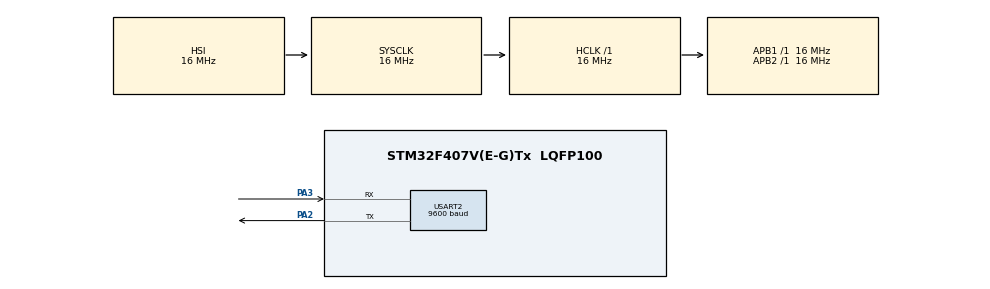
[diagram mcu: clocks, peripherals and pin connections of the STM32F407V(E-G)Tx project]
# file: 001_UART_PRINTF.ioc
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FREERTOS.Tasks01=task2,0,128,gorev2,Default,NULL,Dynamic,NULL,NULL;task1,-3,128,gorev1,Default,NULL,Dynamic,NULL,NULL
FREERTOS.configUSE_NEWLIB_REENTRANT=1
Mcu.Family=STM32F4
Mcu.Name=STM32F407V(E-G)Tx
Mcu.Package=LQFP100
NVIC.PriorityGroup=NVIC_PRIORITYGROUP_4
NVIC.TIM1_UP_TIM10_IRQn=true\:15\:0\:false\:false\:true\:false\:false\:true\:true
NVIC.TimeBase=TIM1_UP_TIM10_IRQn
NVIC.TimeBaseIP=TIM1
NVIC.USART2_IRQn=true\:5\:0\:false\:false\:true\:true\:true\:true\:true
PA2.Mode=Asynchronous
PA2.Signal=USART2_TX
PA3.Mode=Asynchronous
PA3.Signal=USART2_RX
ProjectManager.HeapSize=0x200
ProjectManager.StackSize=0x400
ProjectManager.TargetToolchain=STM32CubeIDE
RCC.AHBFreq_Value=16000000
RCC.APB1Freq_Value=16000000
RCC.APB2Freq_Value=16000000
RCC.CortexFreq_Value=16000000
RCC.HSE_VALUE=25000000
RCC.HSI_VALUE=16000000
RCC.LSE_VALUE=32768
RCC.SYSCLKFreq_VALUE=16000000
RCC.VCOOutputFreq_Value=192000000
USART2.BaudRate=9600
USART2.VirtualMode=VM_ASYNC
VP_FREERTOS_VS_CMSIS_V1.Mode=CMSIS_V1
VP_SYS_VS_tim1.Mode=TIM1
board=custom

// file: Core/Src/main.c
/* USER CODE BEGIN Header */
/**
  ******************************************************************************
  * @file           : main.c
  * @brief          : Main program body
  ******************************************************************************
  * @attention
  *
  * Copyright (c) 2025 STMicroelectronics.
  * All rights reserved.
  *
  * This software is licensed under terms that can be found in the LICENSE file
  * in the root directory of this software component.
  * If no LICENSE file comes with this software, it is provided AS-IS.
  *
  ******************************************************************************
  */
/* USER CODE END Header */
#include "main.h"
#include "cmsis_os.h"

/* USER CODE BEGIN Includes */

#include "stdio.h"
#include <string.h>

/* USER CODE END Includes */

/* USER CODE BEGIN PTD */

#define RED  "\x1B[31m"
#define GRN  "\x1B[32m"

#define RST  "\033[0m"
#define CLR_LINE "\r\033[K"

/* USER CODE END PTD */

/* USER CODE BEGIN PD */

#ifndef STDIN_FILENO
#define STDIN_FILENO 0
#endif

#ifndef STDOUT_FILENO
#define STDOUT_FILENO 1
#endif

#ifndef STDERR_FILENO
#define STDERR_FILENO 2
#endif

/* USER CODE END PD */

UART_HandleTypeDef huart2;

osThreadId task2Handle;
osThreadId task1Handle;
/* USER CODE BEGIN PV */

	uint8_t rxData;
	HAL_StatusTypeDef status;
	char ch[6];
	char input[10];

/* USER CODE END PV */

void SystemClock_Config(void);
static void MX_GPIO_Init(void);
static void MX_USART2_UART_Init(void);
void gorev2(void const * argument);
void gorev1(void const * argument);

/* USER CODE BEGIN 0 */

int _write(int file, char *ptr, int len)
{
	if(file==STDERR_FILENO)
	{
		HAL_UART_Transmit(&huart2, (uint8_t*)RED, strlen(RED) , HAL_MAX_DELAY);
		HAL_UART_Transmit(&huart2, (uint8_t*)ptr, len , HAL_MAX_DELAY);
		HAL_UART_Transmit(&huart2, (uint8_t*)RST, strlen(RST) , HAL_MAX_DELAY);
	}

	else if(file==STDOUT_FILENO)
	{
		HAL_UART_Transmit(&huart2, (uint8_t*)GRN, strlen(GRN) , HAL_MAX_DELAY);
		HAL_UART_Transmit(&huart2, (uint8_t*)ptr, len , HAL_MAX_DELAY);
		HAL_UART_Transmit(&huart2, (uint8_t*)RST, strlen(GRN) , HAL_MAX_DELAY);
	}
	else
	{
		HAL_UART_Transmit(&huart2, (uint8_t*)ptr, len , HAL_MAX_DELAY);

	}
	return len;
}

int _read(int file, char *ptr, int len)
{
    if (file == STDIN_FILENO)
    {
        int i = 0;
        uint8_t ch;

        while (i < len - 1)
        {
            // 1 saniye zaman aşımı ile tek karakter oku
            HAL_StatusTypeDef status = HAL_UART_Receive(&huart2, &ch, 1, 1000);
            if (status == HAL_OK)
            {
                if (ch == '\r' || ch == '\n') // CR veya LF gelirse sonlandır
                {
                    ptr[i] = '\0';
                    break;
                }
                ptr[i++] = ch;
            }
            else
            {
                // Hata veya zaman aşımı durumunda
                ptr[i] = '\0';
                fprintf(stderr, "UART read error: %d\r\n", status);
                return i; // Alınan veriyi döndür veya 0
            }
        }
        ptr[i] = '\0';
        return i;
    }
    return 0;
}

/* USER CODE END 0 */

int main(void)
{

  /* MCU Configuration--------------------------------------------------------*/

  /* Reset of all peripherals, Initializes the Flash interface and the Systick. */
  HAL_Init();

  /* Configure the system clock */
  SystemClock_Config();

  /* Initialize all configured peripherals */
  MX_GPIO_Init();
  MX_USART2_UART_Init();

  /* Create the thread(s) */
  /* definition and creation of task2 */
  osThreadDef(task2, gorev2, osPriorityNormal, 0, 128);
  task2Handle = osThreadCreate(osThread(task2), NULL);

  /* definition and creation of task1 */
  osThreadDef(task1, gorev1, osPriorityIdle, 0, 128);
  task1Handle = osThreadCreate(osThread(task1), NULL);

  /* Start scheduler */
  osKernelStart();

  /* We should never get here as control is now taken by the scheduler */

  /* Infinite loop */
  while (1)
  {

  }
}

void SystemClock_Config(void)
{
  RCC_OscInitTypeDef RCC_OscInitStruct = {0};
  RCC_ClkInitTypeDef RCC_ClkInitStruct = {0};

  /** Configure the main internal regulator output voltage
  */
  __HAL_RCC_PWR_CLK_ENABLE();
  __HAL_PWR_VOLTAGESCALING_CONFIG(PWR_REGULATOR_VOLTAGE_SCALE1);

  /** Initializes the RCC Oscillators according to the specified parameters
  * in the RCC_OscInitTypeDef structure.
  */
  RCC_OscInitStruct.OscillatorType = RCC_OSCILLATORTYPE_HSI;
  RCC_OscInitStruct.HSIState = RCC_HSI_ON;
  RCC_OscInitStruct.HSICalibrationValue = RCC_HSICALIBRATION_DEFAULT;
  RCC_OscInitStruct.PLL.PLLState = RCC_PLL_NONE;
  if (HAL_RCC_OscConfig(&RCC_OscInitStruct) != HAL_OK)
  {
    Error_Handler();
  }

  /** Initializes the CPU, AHB and APB buses clocks
  */
  RCC_ClkInitStruct.ClockType = RCC_CLOCKTYPE_HCLK|RCC_CLOCKTYPE_SYSCLK
                              |RCC_CLOCKTYPE_PCLK1|RCC_CLOCKTYPE_PCLK2;
  RCC_ClkInitStruct.SYSCLKSource = RCC_SYSCLKSOURCE_HSI;
  RCC_ClkInitStruct.AHBCLKDivider = RCC_SYSCLK_DIV1;
  RCC_ClkInitStruct.APB1CLKDivider = RCC_HCLK_DIV1;
  RCC_ClkInitStruct.APB2CLKDivider = RCC_HCLK_DIV1;

  if (HAL_RCC_ClockConfig(&RCC_ClkInitStruct, FLASH_LATENCY_0) != HAL_OK)
  {
    Error_Handler();
  }
}

static void MX_USART2_UART_Init(void)
{

  huart2.Instance = USART2;
  huart2.Init.BaudRate = 9600;
  huart2.Init.WordLength = UART_WORDLENGTH_8B;
  huart2.Init.StopBits = UART_STOPBITS_1;
  huart2.Init.Parity = UART_PARITY_NONE;
  huart2.Init.Mode = UART_MODE_TX_RX;
  huart2.Init.HwFlowCtl = UART_HWCONTROL_NONE;
  huart2.Init.OverSampling = UART_OVERSAMPLING_16;
  if (HAL_UART_Init(&huart2) != HAL_OK)
  {
    Error_Handler();
  }

}

static void MX_GPIO_Init(void)
{

  /* GPIO Ports Clock Enable */
  __HAL_RCC_GPIOA_CLK_ENABLE();

}

void gorev2(void const * argument)
{
  /* USER CODE BEGIN 5 */

    fprintf(stdout, "System initialized\r\n");

    for (;;)
    {
        memset(input, 0, sizeof(input));
        fprintf(stdout, "> "); // Prompt

        if (fgets(input, sizeof(input), stdin) != NULL)
        {
            input[strcspn(input, "\r\n")] = '\0'; // Satır sonunu temizle

            if (strlen(input) == 1 && input[0] == 's')
            {
                fprintf(stdout, "Received 's'\r\n");
            }
            else if (strlen(input) > 0)
            {
                fprintf(stderr, "Invalid input: %s (length: %d)\r\n", input, strlen(input));
            }
            else
            {
                fprintf(stderr, "Empty input received\r\n");
            }
        }
        else
        {
            fprintf(stderr, "Error reading input from fgets\r\n");
        }

        osDelay(10); // Daha hızlı tepki için 50ms -> 10ms
    }
  /* USER CODE END 5 */
}

void gorev1(void const * argument)
{
  /* USER CODE BEGIN gorev1 */
  /* Infinite loop */
  for(;;)
  {

	  osDelay(50);
  }
  /* USER CODE END gorev1 */
}

void HAL_TIM_PeriodElapsedCallback(TIM_HandleTypeDef *htim)
{
  if (htim->Instance == TIM1) {
    HAL_IncTick();
  }
}

void Error_Handler(void)
{
  __disable_irq();
  while (1)
  {
  }
}
